# ATSAMA5D27 register map
Vendor: Microchip Technology Inc.; File version: 1.0
CPU: CA5 r0p1, little endian, no MPU, no FPU, 4 interrupt priority bits
Address unit: 32 bits
Registers are 32-bit, read-write, reset 0x0 unless marked. A register's access mark holds for its fields unless they carry their own. Offsets are from the block's base; [hi:lo] are bit positions; {n}, {i} and the like mark numbered series.

## TWIHS0 — Two-wire Interface High Speed
Base 0xF8028000
Same registers: TWIHS1 0xFC028000
0x00 CR wo — Control Register
  [29] FIFODIS rw — FIFO Disable
  [28] FIFOEN rw — FIFO Enable
  [26] LOCKCLR rw — Lock Clear
  [26] TXFLCLR rw — Transmit FIFO Lock CLEAR
  [25] RXFCLR rw — Receive FIFO Clear
  [24] THRCLR rw — Transmit Holding Register Clear
  [24] TXFCLR rw — Transmit FIFO Clear
  [17] ACMDIS rw — Alternative Command Mode Disable
  [16] ACMEN rw — Alternative Command Mode Enable
  [15] CLEAR rw — Bus CLEAR Command
  [14] PECRQ rw — PEC Request
  [13] PECDIS rw — Packet Error Checking Disable
  [12] PECEN rw — Packet Error Checking Enable
  [11] SMBDIS rw — SMBus Mode Disabled
  [10] SMBEN rw — SMBus Mode Enabled
  [9] HSDIS rw — TWIHS High-Speed Mode Disabled
  [8] HSEN rw — TWIHS High-Speed Mode Enabled
  [7] SWRST rw — Software Reset
  [6] QUICK rw — SMBus Quick Command
  [5] SVDIS rw — TWIHS Slave Mode Disabled
  [4] SVEN rw — TWIHS Slave Mode Enabled
  [3] MSDIS rw — TWIHS Master Mode Disabled
  [2] MSEN rw — TWIHS Master Mode Enabled
  [1] STOP rw — Send a STOP Condition
  [0] START rw — Send a START Condition
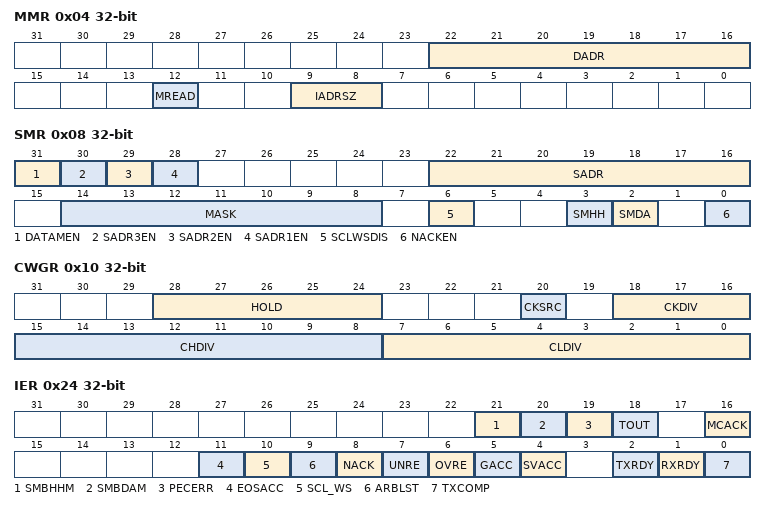
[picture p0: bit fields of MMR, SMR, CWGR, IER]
0x04 MMR — Master Mode Register
  [22:16] DADR — Device Address
  [12] MREAD — Master Read Direction
  [9:8] IADRSZ — Internal Device Address Size
    0=NONE (No internal device address); 1=_1_BYTE (One-byte internal device address); 2=_2_BYTE (Two-byte internal device address); 3=_3_BYTE (Three-byte internal device address)
0x08 SMR — Slave Mode Register
  [31] DATAMEN — Data Matching Enable
  [30] SADR3EN — Slave Address 3 Enable
  [29] SADR2EN — Slave Address 2 Enable
  [28] SADR1EN — Slave Address 1 Enable
  [22:16] SADR — Slave Address
  [14:8] MASK — Slave Address Mask
  [6] SCLWSDIS — Clock Wait State Disable
  [3] SMHH — SMBus Host Header
  [2] SMDA — SMBus Default Address
  [0] NACKEN — Slave Receiver Data Phase NACK enable
0x0C IADR — Internal Address Register
  [23:0] IADR — Internal Address
0x10 CWGR — Clock Waveform Generator Register
  [28:24] HOLD — TWD Hold Time Versus TWCK Falling
  [20] CKSRC — Transfer Rate Clock Source
    0=PERIPH_CK (Peripheral clock is used to generate the TWIHS baud rate.); 1=GCLK (GCLK is used to generate the TWIHS baud rate.)
  [18:16] CKDIV — Clock Divider
  [15:8] CHDIV — Clock High Divider
  [7:0] CLDIV — Clock Low Divider
0x20 SR ro — Status Register
  [25] SDA rw — SDA Line Value
  [24] SCL rw — SCL Line Value
  [23] LOCK rw — TWIHS Lock due to Frame Errors (cleared by writing a one to bit LOCKCLR in TWIHS_CR)
  [23] TXFLOCK rw — Transmit FIFO Lock
  [21] SMBHHM rw — SMBus Host Header Address Match (cleared on read)
  [20] SMBDAM rw — SMBus Default Address Match (cleared on read)
  [19] PECERR rw — PEC Error (cleared on read)
  [18] TOUT rw — Timeout Error (cleared on read)
  [16] MCACK rw — Master Code Acknowledge (cleared on read)
  [11] EOSACC rw — End Of Slave Access (cleared on read)
  [10] SCLWS rw — Clock Wait State
  [9] ARBLST rw — Arbitration Lost (cleared on read)
  [8] NACK rw — Not Acknowledged (cleared on read)
  [7] UNRE rw — Underrun Error (cleared on read)
  [6] OVRE rw — Overrun Error (cleared on read)
  [5] GACC rw — General Call Access (cleared on read)
  [4] SVACC rw — Slave Access
  [3] SVREAD rw — Slave Read
  [2] TXRDY rw — Transmit Holding Register Ready (cleared by writing TWIHS_THR)
  [1] RXRDY rw — Receive Holding Register Ready (cleared by reading TWIHS_RHR)
  [0] TXCOMP rw — Transmission Completed (cleared by writing TWIHS_THR)
0x24 IER wo — Interrupt Enable Register
  [21] SMBHHM rw — SMBus Host Header Address Match Interrupt Enable
  [20] SMBDAM rw — SMBus Default Address Match Interrupt Enable
  [19] PECERR rw — PEC Error Interrupt Enable
  [18] TOUT rw — Timeout Error Interrupt Enable
  [16] MCACK rw — Master Code Acknowledge Interrupt Enable
  [11] EOSACC rw — End Of Slave Access Interrupt Enable
  [10] SCL_WS rw — Clock Wait State Interrupt Enable
  [9] ARBLST rw — Arbitration Lost Interrupt Enable
  [8] NACK rw — Not Acknowledge Interrupt Enable
  [7] UNRE rw — Underrun Error Interrupt Enable
  [6] OVRE rw — Overrun Error Interrupt Enable
  [5] GACC rw — General Call Access Interrupt Enable
  [4] SVACC rw — Slave Access Interrupt Enable
  [2] TXRDY rw — Transmit Holding Register Ready Interrupt Enable
  [1] RXRDY rw — Receive Holding Register Ready Interrupt Enable
  [0] TXCOMP rw — Transmission Completed Interrupt Enable
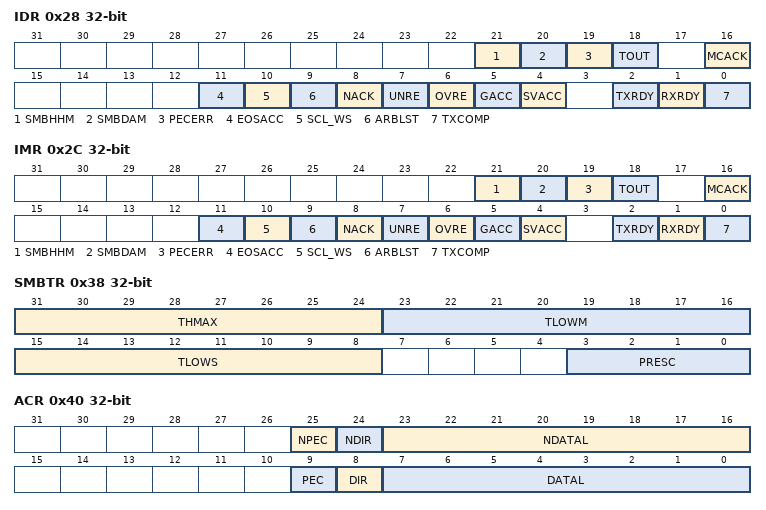
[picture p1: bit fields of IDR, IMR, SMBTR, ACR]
0x28 IDR wo — Interrupt Disable Register
  [21] SMBHHM rw — SMBus Host Header Address Match Interrupt Disable
  [20] SMBDAM rw — SMBus Default Address Match Interrupt Disable
  [19] PECERR rw — PEC Error Interrupt Disable
  [18] TOUT rw — Timeout Error Interrupt Disable
  [16] MCACK rw — Master Code Acknowledge Interrupt Disable
  [11] EOSACC rw — End Of Slave Access Interrupt Disable
  [10] SCL_WS rw — Clock Wait State Interrupt Disable
  [9] ARBLST rw — Arbitration Lost Interrupt Disable
  [8] NACK rw — Not Acknowledge Interrupt Disable
  [7] UNRE rw — Underrun Error Interrupt Disable
  [6] OVRE rw — Overrun Error Interrupt Disable
  [5] GACC rw — General Call Access Interrupt Disable
  [4] SVACC rw — Slave Access Interrupt Disable
  [2] TXRDY rw — Transmit Holding Register Ready Interrupt Disable
  [1] RXRDY rw — Receive Holding Register Ready Interrupt Disable
  [0] TXCOMP rw — Transmission Completed Interrupt Disable
0x2C IMR ro — Interrupt Mask Register
  [21] SMBHHM rw — SMBus Host Header Address Match Interrupt Mask
  [20] SMBDAM rw — SMBus Default Address Match Interrupt Mask
  [19] PECERR rw — PEC Error Interrupt Mask
  [18] TOUT rw — Timeout Error Interrupt Mask
  [16] MCACK rw — Master Code Acknowledge Interrupt Mask
  [11] EOSACC rw — End Of Slave Access Interrupt Mask
  [10] SCL_WS rw — Clock Wait State Interrupt Mask
  [9] ARBLST rw — Arbitration Lost Interrupt Mask
  [8] NACK rw — Not Acknowledge Interrupt Mask
  [7] UNRE rw — Underrun Error Interrupt Mask
  [6] OVRE rw — Overrun Error Interrupt Mask
  [5] GACC rw — General Call Access Interrupt Mask
  [4] SVACC rw — Slave Access Interrupt Mask
  [2] TXRDY rw — Transmit Holding Register Ready Interrupt Mask
  [1] RXRDY rw — Receive Holding Register Ready Interrupt Mask
  [0] TXCOMP rw — Transmission Completed Interrupt Mask
0x30 RHR ro — Receive Holding Register
  [8n+7:8n] RXDATA{n} rw (n=0..3) — Master or Slave Receive Holding Data {n}
  [7:0] RXDATA rw — Master or Slave Receive Holding Data
0x34 THR wo — Transmit Holding Register
  [31:24] TXDATA3 rw — Master or Slave Transmit Holding Data 3
  [23:16] TXDATA2 rw — Master or Slave Transmit Holding Data 2
  [15:8] TXDATA1 rw — Master or Slave Transmit Holding Data 1
  [7:0] TXDATA rw — Master or Slave Transmit Holding Data
  [7:0] TXDATA0 rw — Master or Slave Transmit Holding Data 02
0x38 SMBTR — SMBus Timing Register
  [31:24] THMAX — Clock High Maximum Cycles
  [23:16] TLOWM — Master Clock Stretch Maximum Cycles
  [15:8] TLOWS — Slave Clock Stretch Maximum Cycles
  [3:0] PRESC — SMBus Clock Prescaler
0x40 ACR — Alternative Command Register
  [25] NPEC — Next PEC Request (SMBus Mode only)
  [24] NDIR — Next Transfer Direction
  [23:16] NDATAL — Next Data Length
  [9] PEC — PEC Request (SMBus Mode only)
  [8] DIR — Transfer Direction
  [7:0] DATAL — Data Length
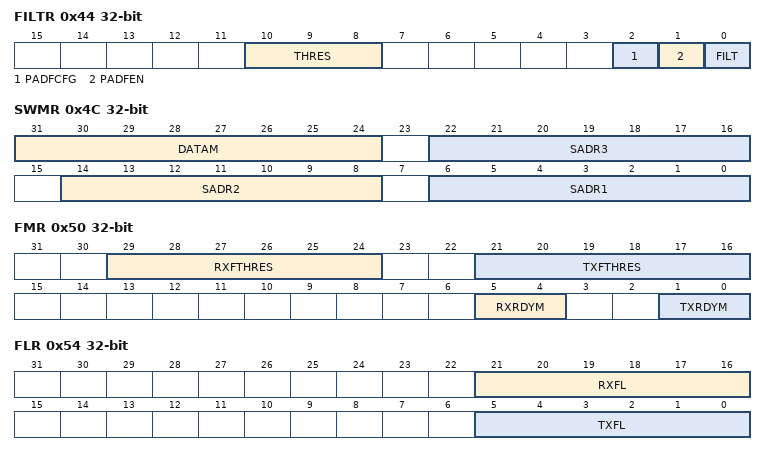
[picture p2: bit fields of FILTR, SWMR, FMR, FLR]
0x44 FILTR — Filter Register
  [10:8] THRES — Digital Filter Threshold
  [2] PADFCFG — PAD Filter Config
  [1] PADFEN — PAD Filter Enable
  [0] FILT — RX Digital Filter
0x4C SWMR — SleepWalking Matching Register
  [31:24] DATAM — Data Match
  [22:16] SADR3 — Slave Address 3
  [14:8] SADR2 — Slave Address 2
  [6:0] SADR1 — Slave Address 1
0x50 FMR — FIFO Mode Register
  [29:24] RXFTHRES — Receive FIFO Threshold
  [21:16] TXFTHRES — Transmit FIFO Threshold
  [5:4] RXRDYM — Receiver Ready Mode
    0=ONE_DATA (RXRDY will be at level '1' when at least one unread data is in the Receive FIFO); 1=TWO_DATA (RXRDY will be at level '1' when at least two unread data are in the Receive FIFO); 2=FOUR_DATA (RXRDY will be at level '1' when at least four unread data are in the Receive FIFO)
  [1:0] TXRDYM — Transmitter Ready Mode
    0=ONE_DATA (TXRDY will be at level '1' when at least one data can be written in the Transmit FIFO); 1=TWO_DATA (TXRDY will be at level '1' when at least two data can be written in the Transmit FIFO); 2=FOUR_DATA (TXRDY will be at level '1' when at least four data can be written in the Transmit FIFO)
0x54 FLR ro — FIFO Level Register
  [21:16] RXFL rw — Receive FIFO Level
  [5:0] TXFL rw — Transmit FIFO Level
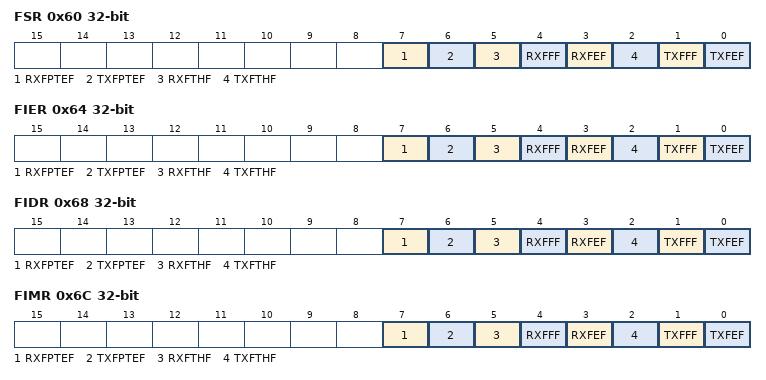
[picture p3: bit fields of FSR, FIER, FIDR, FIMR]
0x60 FSR ro — FIFO Status Register
  [7] RXFPTEF rw — Receive FIFO Pointer Error Flag
  [6] TXFPTEF rw — Transmit FIFO Pointer Error Flag
  [5] RXFTHF rw — Receive FIFO Threshold Flag
  [4] RXFFF rw — Receive FIFO Full Flag
  [3] RXFEF rw — Receive FIFO Empty Flag
  [2] TXFTHF rw — Transmit FIFO Threshold Flag (cleared on read)
  [1] TXFFF rw — Transmit FIFO Full Flag (cleared on read)
  [0] TXFEF rw — Transmit FIFO Empty Flag (cleared on read)
0x64 FIER wo — FIFO Interrupt Enable Register
  [7] RXFPTEF rw — RXFPTEF Interrupt Enable
  [6] TXFPTEF rw — TXFPTEF Interrupt Enable
  [5] RXFTHF rw — RXFTHF Interrupt Enable
  [4] RXFFF rw — RXFFF Interrupt Enable
  [3] RXFEF rw — RXFEF Interrupt Enable
  [2] TXFTHF rw — TXFTHF Interrupt Enable
  [1] TXFFF rw — TXFFF Interrupt Enable
  [0] TXFEF rw — TXFEF Interrupt Enable
0x68 FIDR wo — FIFO Interrupt Disable Register
  [7] RXFPTEF rw — RXFPTEF Interrupt Disable
  [6] TXFPTEF rw — TXFPTEF Interrupt Disable
  [5] RXFTHF rw — RXFTHF Interrupt Disable
  [4] RXFFF rw — RXFFF Interrupt Disable
  [3] RXFEF rw — RXFEF Interrupt Disable
  [2] TXFTHF rw — TXFTHF Interrupt Disable
  [1] TXFFF rw — TXFFF Interrupt Disable
  [0] TXFEF rw — TXFEF Interrupt Disable
0x6C FIMR ro — FIFO Interrupt Mask Register
  [7] RXFPTEF rw — RXFPTEF Interrupt Mask
  [6] TXFPTEF rw — TXFPTEF Interrupt Mask
  [5] RXFTHF rw — RXFTHF Interrupt Mask
  [4] RXFFF rw — RXFFF Interrupt Mask
  [3] RXFEF rw — RXFEF Interrupt Mask
  [2] TXFTHF rw — TXFTHF Interrupt Mask
  [1] TXFFF rw — TXFFF Interrupt Mask
  [0] TXFEF rw — TXFEF Interrupt Mask
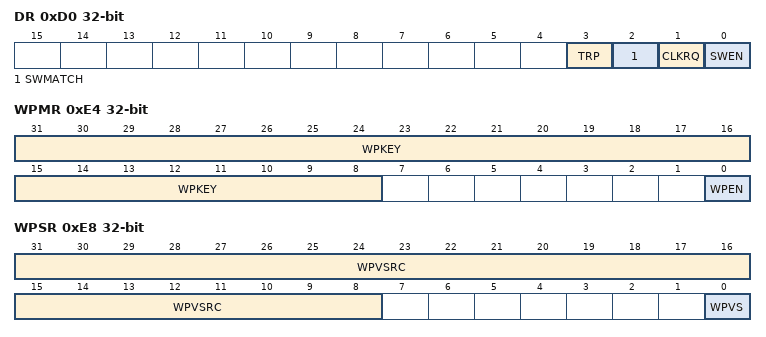
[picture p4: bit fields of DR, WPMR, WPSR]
0xD0 DR ro — Debug Register
  [3] TRP rw — Transfer Pending
  [2] SWMATCH rw — SleepWalking Match
  [1] CLKRQ rw — Clock Request
  [0] SWEN rw — SleepWalking Enable
0xE4 WPMR — Write Protection Mode Register
  [31:8] WPKEY — Write Protection Key
    0x545749=PASSWD (Writing any other value in this field aborts the write operation of the WPEN bit.Always reads as 0)
  [0] WPEN — Write Protection Enable
0xE8 WPSR ro — Write Protection Status Register
  [31:8] WPVSRC rw — Write Protection Violation Source
  [0] WPVS rw — Write Protection Violation Status
